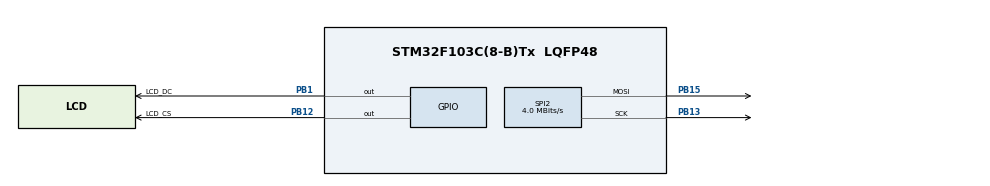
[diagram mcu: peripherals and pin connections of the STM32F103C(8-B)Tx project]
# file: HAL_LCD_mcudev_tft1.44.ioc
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Mcu.Family=STM32F1
Mcu.Name=STM32F103C(8-B)Tx
Mcu.Package=LQFP48
NVIC.PriorityGroup=NVIC_PRIORITYGROUP_4
PA13.Mode=JTAG_5_pins
PA13.Signal=SYS_JTMS-SWDIO
PA14.Mode=JTAG_5_pins
PA14.Signal=SYS_JTCK-SWCLK
PA15.Mode=JTAG_5_pins
PA15.Signal=SYS_JTDI
PB1.GPIO_Label=LCD_DC
PB1.Signal=GPIO_Output
PB12.GPIO_Label=LCD_CS
PB12.Signal=GPIO_Output
PB13.Mode=TX_Only_Simplex_Unidirect_Master
PB13.Signal=SPI2_SCK
PB15.Mode=TX_Only_Simplex_Unidirect_Master
PB15.Signal=SPI2_MOSI
PB3.Mode=JTAG_5_pins
PB3.Signal=SYS_JTDO-TRACESWO
PB4.Mode=JTAG_5_pins
PB4.Signal=SYS_NJTRST
ProjectManager.HeapSize=0x200
ProjectManager.StackSize=0x400
ProjectManager.TargetToolchain=STM32CubeIDE
RCC.APB1Freq_Value=8000000
RCC.APB2Freq_Value=8000000
SPI2.CalculateBaudRate=4.0 MBits/s
SPI2.Direction=SPI_DIRECTION_2LINES
SPI2.Mode=SPI_MODE_MASTER
SPI2.VirtualType=VM_MASTER
board=custom

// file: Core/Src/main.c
/* USER CODE BEGIN Header */
/**
  ******************************************************************************
  * @file           : main.c
  * @brief          : Main program body
  ******************************************************************************
  * @attention
  *
  * Copyright (c) 2024 STMicroelectronics.
  * All rights reserved.
  *
  * This software is licensed under terms that can be found in the LICENSE file
  * in the root directory of this software component.
  * If no LICENSE file comes with this software, it is provided AS-IS.
  *
  ******************************************************************************
  */
/* USER CODE END Header */
#include "main.h"

/* USER CODE BEGIN Includes */
#include "LCD_MCUDEV.h"

/* USER CODE END Includes */

SPI_HandleTypeDef hspi2;

void SystemClock_Config(void);
static void MX_GPIO_Init(void);
static void MX_SPI2_Init(void);

/* USER CODE BEGIN 0 */
//void my_fill(void)
//{
//	lcd_set_window(x, y, width, height);
//	lcd_cmd(ST7735S_RAMWR);
//	for (int i = 0; i < width * height; i++)
//
//	uint16_t color = RED;
//	HAL_GPIO_WritePin(LCD_DC_GPIO_Port, LCD_DC_Pin, GPIO_PIN_SET);
//	HAL_GPIO_WritePin(LCD_CS_GPIO_Port, LCD_CS_Pin, GPIO_PIN_RESET);
//	HAL_SPI_Transmit(&hspi2, &data, 1, HAL_MAX_DELAY);
//	HAL_GPIO_WritePin(LCD_CS_GPIO_Port, LCD_CS_Pin, GPIO_PIN_SET);
//
//}
/* USER CODE END 0 */

int main(void)
{

  /* MCU Configuration--------------------------------------------------------*/

  /* Reset of all peripherals, Initializes the Flash interface and the Systick. */
  HAL_Init();

  /* Configure the system clock */
  SystemClock_Config();

  /* Initialize all configured peripherals */
  MX_GPIO_Init();
  MX_SPI2_Init();
  /* USER CODE BEGIN 2 */

  lcd_init();

  //lcd_send(0x139);
  /* USER CODE END 2 */

  /* Infinite loop */
  while (1)
  {

	  lcd_fill_box(0, 0, 64, 160, RED);
	  HAL_Delay(5000);
	  lcd_fill_box(64, 0, 128, 160, GREEN);
	  HAL_Delay(5000);
	  lcd_fill_box(0, 0, 64, 160, BLUE);
	  HAL_Delay(5000);
	  lcd_fill_box(64, 0, 128, 160, BLACK);
	  HAL_Delay(5000);

//	  HAL_Delay(1000);
//	  lcd_send(0x138);

  }
}

void SystemClock_Config(void)
{
  RCC_OscInitTypeDef RCC_OscInitStruct = {0};
  RCC_ClkInitTypeDef RCC_ClkInitStruct = {0};

  /** Initializes the RCC Oscillators according to the specified parameters
  * in the RCC_OscInitTypeDef structure.
  */
  RCC_OscInitStruct.OscillatorType = RCC_OSCILLATORTYPE_HSI;
  RCC_OscInitStruct.HSIState = RCC_HSI_ON;
  RCC_OscInitStruct.HSICalibrationValue = RCC_HSICALIBRATION_DEFAULT;
  RCC_OscInitStruct.PLL.PLLState = RCC_PLL_NONE;
  if (HAL_RCC_OscConfig(&RCC_OscInitStruct) != HAL_OK)
  {
    Error_Handler();
  }

  /** Initializes the CPU, AHB and APB buses clocks
  */
  RCC_ClkInitStruct.ClockType = RCC_CLOCKTYPE_HCLK|RCC_CLOCKTYPE_SYSCLK
                              |RCC_CLOCKTYPE_PCLK1|RCC_CLOCKTYPE_PCLK2;
  RCC_ClkInitStruct.SYSCLKSource = RCC_SYSCLKSOURCE_HSI;
  RCC_ClkInitStruct.AHBCLKDivider = RCC_SYSCLK_DIV1;
  RCC_ClkInitStruct.APB1CLKDivider = RCC_HCLK_DIV1;
  RCC_ClkInitStruct.APB2CLKDivider = RCC_HCLK_DIV1;

  if (HAL_RCC_ClockConfig(&RCC_ClkInitStruct, FLASH_LATENCY_0) != HAL_OK)
  {
    Error_Handler();
  }
}

static void MX_SPI2_Init(void)
{

  /* SPI2 parameter configuration*/
  hspi2.Instance = SPI2;
  hspi2.Init.Mode = SPI_MODE_MASTER;
  hspi2.Init.Direction = SPI_DIRECTION_2LINES;
  hspi2.Init.DataSize = SPI_DATASIZE_8BIT;
  hspi2.Init.CLKPolarity = SPI_POLARITY_LOW;
  hspi2.Init.CLKPhase = SPI_PHASE_1EDGE;
  hspi2.Init.NSS = SPI_NSS_SOFT;
  hspi2.Init.BaudRatePrescaler = SPI_BAUDRATEPRESCALER_2;
  hspi2.Init.FirstBit = SPI_FIRSTBIT_MSB;
  hspi2.Init.TIMode = SPI_TIMODE_DISABLE;
  hspi2.Init.CRCCalculation = SPI_CRCCALCULATION_DISABLE;
  hspi2.Init.CRCPolynomial = 10;
  if (HAL_SPI_Init(&hspi2) != HAL_OK)
  {
    Error_Handler();
  }

}

static void MX_GPIO_Init(void)
{
  GPIO_InitTypeDef GPIO_InitStruct = {0};

  /* GPIO Ports Clock Enable */
  __HAL_RCC_GPIOB_CLK_ENABLE();
  __HAL_RCC_GPIOA_CLK_ENABLE();

  /*Configure GPIO pin Output Level */
  HAL_GPIO_WritePin(GPIOB, LCD_DC_Pin|LCD_CS_Pin, GPIO_PIN_RESET);

  /*Configure GPIO pins : LCD_DC_Pin LCD_CS_Pin */
  GPIO_InitStruct.Pin = LCD_DC_Pin|LCD_CS_Pin;
  GPIO_InitStruct.Mode = GPIO_MODE_OUTPUT_PP;
  GPIO_InitStruct.Pull = GPIO_NOPULL;
  GPIO_InitStruct.Speed = GPIO_SPEED_FREQ_LOW;
  HAL_GPIO_Init(GPIOB, &GPIO_InitStruct);

}

void Error_Handler(void)
{
  __disable_irq();
  while (1)
  {
  }
}
